AUTOSAR XML (schema 00046)
package /APP_swc
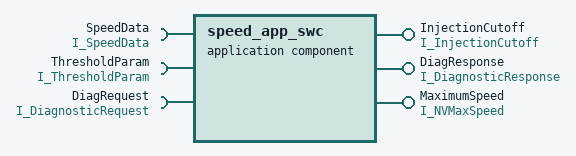
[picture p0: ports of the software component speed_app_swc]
  application sw component type speed_app_swc
    require port SpeedData: required-interface=I_SpeedData
    require port ThresholdParam: required-interface=I_ThresholdParam
    provide port InjectionCutoff: provided-interface=I_InjectionCutoff
    require port DiagRequest: required-interface=I_DiagnosticRequest
    provide port DiagResponse: provided-interface=I_DiagnosticResponse
    provide port MaximumSpeed: provided-interface=I_NVMaxSpeed
    behavior IB_App_swc
      4 x timing event:
        SpeedSensorData: start-on-event=SpeedMonitoring
        Overspeed: start-on-event=InjectionCutoff
        DiagnosticRequestEvent: start-on-event=DiagnosticRequestHandler
        DrivingCycleEnd: start-on-event=DataStorage
      5 x runnable:
        SpeedMonitoring: symbol=vehical_spped_monitor
          data-receive-point-by-arguments:
            access VA_Speed: accessed-variable=SpeedData.VehicleSpeed
        SpeedCalculation: symbol=vehical_speed_calculation
          data-receive-point-by-arguments:
            access VA_speed_calculate: accessed-variable=ThresholdParam.SpeedThreshold
        DiagnosticRequestHandler: symbol=diagnostic_process
          sync call SC_SendDiagRequest: operation=DiagRequest.SendDiagnosticRequest
          sync call SC_SendDiagResponse: operation=DiagResponse.SendDiagnosticResponse
        InjectionCutoff: symbol=Fuel_injuction_cutoff
          data-receive-point-by-arguments:
            access VA_fuel_cutoff: accessed-variable=InjectionCutoff.InjectionCutoffCommand
        DataStorage: symbol=store_maximum_speed
          data-receive-point-by-arguments:
            access VA_Max_Speed: accessed-variable=MaximumSpeed.NVMaxSpeed
